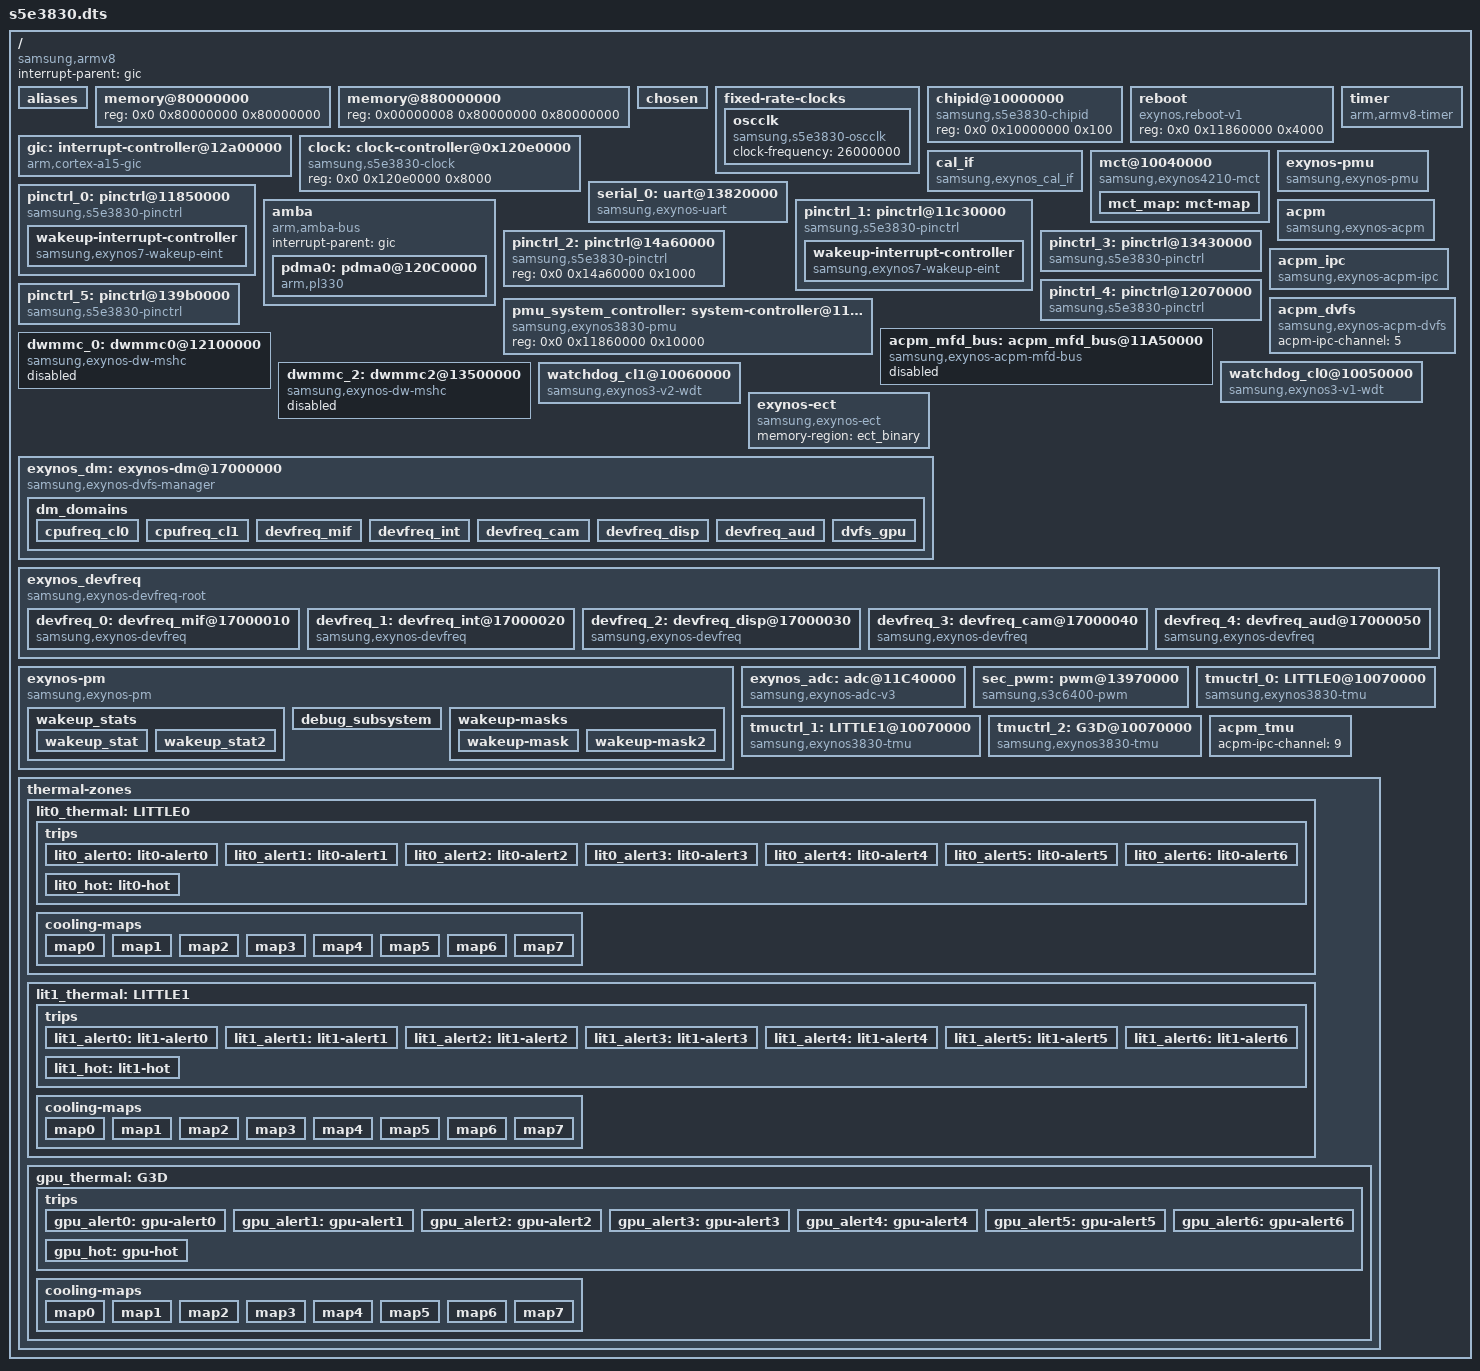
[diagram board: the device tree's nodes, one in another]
/*
 * SAMSUNG EXYNOS3830 SoC device tree source
 *
 * Copyright (c) 2018 Samsung Electronics Co., Ltd.
 *		http://www.samsung.com
 *
 * SAMSUNG EXYNOS3830 SoC device nodes are listed in this file.
 * EXYNOS based board files can include this file and provide
 * values for board specfic bindings.
 *
 * This program is free software; you can redistribute it and/or modify
 * it under the terms of the GNU General Public License version 2 as
 * published by the Free Software Foundation.
 */

/dts-v1/;
//#include <dt-bindings/clock/exynosXXXX.h>
#include <dt-bindings/interrupt-controller/arm-gic.h>
#include <dt-bindings/interrupt-controller/s5e3830.h>
#include <dt-bindings/clock/s5e3830.h>
#include <dt-bindings/soc/samsung/s5e3830-dm.h>
#include <dt-bindings/soc/samsung/s5e3830-devfreq.h>
#include <dt-bindings/soc/samsung/exynos_pm_qos.h>
#include "s5e3830-pinctrl.dtsi"
#include "s5e3830-usi.dtsi"
#include "s5e3830-rmem.dtsi"
#include "s5e3830-debug.dtsi"
#include "s5e3830-dma-heap.dtsi"
#include "s5e3830-sysmmu.dtsi"
#include "s5e3830-mali.dtsi"
#include "s5e3830-cpu.dtsi"
#include "s5e3830-ems.dtsi"
#include "s5e3830-dpu.dtsi"
#include "s5e3830-usb.dtsi"
#include "s5e3830-security.dtsi"
#include "s5e3830-pm-domains.dtsi"
#include "s5e3830-bts.dtsi"
#include "s5e3830-wlbt.dtsi"
#include "s5e3830-m2m.dtsi"

/ {
	compatible = "samsung,armv8", "samsung,exynos3830";
	interrupt-parent = <&gic>;
	#address-cells = <2>;
	#size-cells = <1>;

	aliases {
		pinctrl0 = &pinctrl_0;
		pinctrl1 = &pinctrl_1;
		pinctrl2 = &pinctrl_2;
		pinctrl3 = &pinctrl_3;
		pinctrl4 = &pinctrl_4;
		pinctrl5 = &pinctrl_5;
		uart0 = &serial_0;

		mshc0 = &dwmmc_0;
		mshc2 = &dwmmc_2;
	};

                        memory@80000000 {
                                device_type = "memory";
                                reg = <0x0 0x80000000 0x80000000>;
                        };

                        memory@880000000 {
                                device_type = "memory";
                                reg = <0x00000008 0x80000000 0x80000000>;
                        };

                        chosen {
				bootargs = "earlycon=exynos4210,0x13820000 console=ttySAC0,115200n8 androidboot.console=ttySAC0 s3c2410_wdt.tmr_atboot=1  androidboot.boot_devices=12100000.dwmmc0 clocksource=arch_sys_counter clk_ignore_unused androidboot.hardware=s5e3830 printk.devkmsg=on firmware_class.path=/vendor/firmware";
                                linux,initrd-start = <0x84000000>;
                                linux,initrd-end = <0x847FFFFF>;
                        };

                        fixed-rate-clocks {
                                oscclk {
                                        compatible = "samsung,s5e3830-oscclk";
                                        clock-frequency = <26000000>;
                                };
                        };



	chipid@10000000 {
		compatible = "samsung,s5e3830-chipid";
		reg = <0x0 0x10000000 0x100>;
	};

	reboot {
		compatible = "exynos,reboot-v1";
		reg = <0x0 0x11860000 0x4000>;
	};

	gic:interrupt-controller@12a00000 {
		compatible = "arm,cortex-a15-gic", "arm,cortex-a9-gic";
		#interrupt-cells = <3>;
		#address-cells = <0>;
		interrupt-controller;
		reg =	<0x0 0x12a01000 0x1000>,
			<0x0 0x12a02000 0x1000>,
			<0x0 0x12a04000 0x2000>,
			<0x0 0x12a06000 0x2000>;
		interrupts = <1 9 0xf04>;
	};

	timer {
	        compatible = "arm,armv8-timer";
		interrupts = <GIC_PPI 13
				(GIC_CPU_MASK_SIMPLE(8) | IRQ_TYPE_LEVEL_LOW)>,
			     <GIC_PPI 14
				(GIC_CPU_MASK_SIMPLE(8) | IRQ_TYPE_LEVEL_LOW)>,
			     <GIC_PPI 11
				(GIC_CPU_MASK_SIMPLE(8) | IRQ_TYPE_LEVEL_LOW)>,
			     <GIC_PPI 10
				(GIC_CPU_MASK_SIMPLE(8) | IRQ_TYPE_LEVEL_LOW)>;
	        clock-frequency = <26000000>;
		use-clocksource-only;
		use-physical-timer;
	};

	clock: clock-controller@0x120e0000 {
		compatible = "samsung,s5e3830-clock";
		reg = <0x0 0x120e0000 0x8000>;
		#clock-cells = <1>;
	};

	 cal_if {
                compatible = "samsung,exynos_cal_if";
                reg = <0x0 0x120e0000 0x8000>;
                acpm-ipc-channel = <0>;
        };

	mct@10040000 {
		compatible = "samsung,exynos4210-mct";
		reg = <0x0 0x10040000 0x800>;
		interrupt-controller;
		#interrupt-cells = <1>;
		interrupt-parent = <&mct_map>;
		interrupts =	<0>, <1>, <2>, <3>,
				<4>, <5>, <6>, <7>,
				<8>, <9>, <10>, <11>;
		clocks = <&clock 1>, <&clock 21>;
		clock-names = "fin_pll", "mct";
		use-clockevent-only;

		mct_map: mct-map {
			#interrupt-cells = <1>;
			#address-cells = <0>;
			#size-cells = <0>;
			interrupt-map = <0 &gic 0 INTREQ__MCT_G0 IRQ_TYPE_LEVEL_HIGH>,
					<1 &gic 0 INTREQ__MCT_G1 IRQ_TYPE_LEVEL_HIGH>,
					<2 &gic 0 INTREQ__MCT_G2 IRQ_TYPE_LEVEL_HIGH>,
					<3 &gic 0 INTREQ__MCT_G3 IRQ_TYPE_LEVEL_HIGH>,
					<4 &gic 0 INTREQ__MCT_L0 IRQ_TYPE_LEVEL_HIGH>,
					<5 &gic 0 INTREQ__MCT_L1 IRQ_TYPE_LEVEL_HIGH>,
					<6 &gic 0 INTREQ__MCT_L2 IRQ_TYPE_LEVEL_HIGH>,
					<7 &gic 0 INTREQ__MCT_L3 IRQ_TYPE_LEVEL_HIGH>,
					<8 &gic 0 INTREQ__MCT_L4 IRQ_TYPE_LEVEL_HIGH>,
					<9 &gic 0 INTREQ__MCT_L5 IRQ_TYPE_LEVEL_HIGH>,
					<10 &gic 0 INTREQ__MCT_L6 IRQ_TYPE_LEVEL_HIGH>,
					<11 &gic 0 INTREQ__MCT_L7 IRQ_TYPE_LEVEL_HIGH>;
		};
	};

	serial_0: uart@13820000 {
		compatible = "samsung,exynos-uart";
		samsung,separate-uart-clk;
		reg = <0x0 0x13820000 0x100>;
		samsung,fifo-size = <64>;
		interrupts = <0 INTREQ__UART 0>;
		pinctrl-names = "default";
		pinctrl-0 = <&uart0_bus>;
		samsung,console-dbg;
		samsung,usi-serial-v2;
		samsung,dbg-uart-ch;
		samsung,dbg-uart-baud = <115200>;
		samsung,dbg-word-len = <8>;
		clocks = <&clock GATE_UART_QCH>, <&clock DOUT_UART>;
		clock-names = "gate_uart_clk0", "ipclk_uart0";
		status = "okay";
	};
	/* TBD */
/*
	dwmmc_2: dwmmc2@13D00000 {
		compatible = "samsung,exynos-dw-mshc";
		reg = <0x0 0x13D00000 0x2000>;
		reg-names = "dw_mmc";
		interrupts = <0 250 0>;
		#address-cells = <1>;
		#size-cells = <0>;

		clocks = <&clock MMC_CARD>, <&clock GATE_MMC_CARD>;
		clock-names = "ciu", "ciu_gate";
		status = "disabled";
	 };
*/
	/* ALIVE */
	pinctrl_0: pinctrl@11850000 {
		compatible = "samsung,s5e3830-pinctrl";
		reg = <0x0 0x11850000 0x1000>;
		interrupts = <GIC_SPI INTREQ__ALIVE_EINT0 IRQ_TYPE_LEVEL_HIGH>,
			     <GIC_SPI INTREQ__ALIVE_EINT1 IRQ_TYPE_LEVEL_HIGH>,
			     <GIC_SPI INTREQ__ALIVE_EINT2 IRQ_TYPE_LEVEL_HIGH>,
			     <GIC_SPI INTREQ__ALIVE_EINT3 IRQ_TYPE_LEVEL_HIGH>,
			     <GIC_SPI INTREQ__ALIVE_EINT4 IRQ_TYPE_LEVEL_HIGH>,
			     <GIC_SPI INTREQ__ALIVE_EINT5 IRQ_TYPE_LEVEL_HIGH>,
			     <GIC_SPI INTREQ__ALIVE_EINT6 IRQ_TYPE_LEVEL_HIGH>,
			     <GIC_SPI INTREQ__ALIVE_EINT7 IRQ_TYPE_LEVEL_HIGH>,
			     <GIC_SPI INTREQ__ALIVE_EINT8 IRQ_TYPE_LEVEL_HIGH>,
			     <GIC_SPI INTREQ__ALIVE_EINT9 IRQ_TYPE_LEVEL_HIGH>,
			     <GIC_SPI INTREQ__ALIVE_EINT10 IRQ_TYPE_LEVEL_HIGH>,
			     <GIC_SPI INTREQ__ALIVE_EINT11 IRQ_TYPE_LEVEL_HIGH>,
			     <GIC_SPI INTREQ__ALIVE_EINT12 IRQ_TYPE_LEVEL_HIGH>,
			     <GIC_SPI INTREQ__ALIVE_EINT13 IRQ_TYPE_LEVEL_HIGH>,
			     <GIC_SPI INTREQ__ALIVE_EINT14 IRQ_TYPE_LEVEL_HIGH>,
			     <GIC_SPI INTREQ__ALIVE_EINT15 IRQ_TYPE_LEVEL_HIGH>,
			     <GIC_SPI INTREQ__ALIVE_EINT16 IRQ_TYPE_LEVEL_HIGH>,
			     <GIC_SPI INTREQ__ALIVE_EINT17 IRQ_TYPE_LEVEL_HIGH>,
			     <GIC_SPI INTREQ__ALIVE_EINT18 IRQ_TYPE_LEVEL_HIGH>,
			     <GIC_SPI INTREQ__ALIVE_EINT19 IRQ_TYPE_LEVEL_HIGH>,
			     <GIC_SPI INTREQ__ALIVE_EINT20 IRQ_TYPE_LEVEL_HIGH>,
			     <GIC_SPI INTREQ__ALIVE_EINT21 IRQ_TYPE_LEVEL_HIGH>,
			     <GIC_SPI INTREQ__ALIVE_EINT22 IRQ_TYPE_LEVEL_HIGH>,
			     <GIC_SPI INTREQ__ALIVE_EINT23 IRQ_TYPE_LEVEL_HIGH>,
			     <GIC_SPI INTREQ__ALIVE_EINT24 IRQ_TYPE_LEVEL_HIGH>,
			     <GIC_SPI INTREQ__ALIVE_EINT25 IRQ_TYPE_LEVEL_HIGH>,
			     <GIC_SPI INTREQ__ALIVE_EINT26 IRQ_TYPE_LEVEL_HIGH>,
			     <GIC_SPI INTREQ__ALIVE_EINT27 IRQ_TYPE_LEVEL_HIGH>,
			     <GIC_SPI INTREQ__ALIVE_EINT28 IRQ_TYPE_LEVEL_HIGH>,
			     <GIC_SPI INTREQ__ALIVE_EINT29 IRQ_TYPE_LEVEL_HIGH>,
			     <GIC_SPI INTREQ__ALIVE_EINT30 IRQ_TYPE_LEVEL_HIGH>,
			     <GIC_SPI INTREQ__ALIVE_EINT31 IRQ_TYPE_LEVEL_HIGH>;

		wakeup-interrupt-controller {
			compatible = "samsung,exynos7-wakeup-eint";
		};
	};

	/* DMA */
	amba {
		#address-cells = <2>;
		#size-cells = <1>;
		compatible = "arm,amba-bus";
		interrupt-parent = <&gic>;
		ranges;
		pdma0: pdma0@120C0000 {
			compatible = "arm,pl330", "arm,primecell";
			reg = <0x0 0x120C0000 0x1000>;
			interrupts = <GIC_SPI INTREQ__PDMA0 IRQ_TYPE_LEVEL_HIGH>;
			clocks = <&clock GATE_PDMA_CORE_QCH>;
			clock-names = "apb_pclk";
			#dma-cells = <1>;
			#dma-channels = <8>;
			#dma-requests = <32>;
			#dma-multi-irq = <1>;
			dma-arwrapper = <0x120C4400>,
					<0x120C4420>,
					<0x120C4440>,
					<0x120C4460>,
					<0x120C4480>,
					<0x120C44A0>,
					<0x120C44C0>,
					<0x120C44E0>;
			dma-awwrapper = <0x120C4404>,
					<0x120C4424>,
					<0x120C4444>,
					<0x120C4464>,
					<0x120C4484>,
					<0x120C44A4>,
					<0x120C44C4>,
					<0x120C44E4>;
			dma-instwrapper = <0x120C4500>;
			dma-mask-bit = <36>;
			coherent-mask-bit = <36>;
		};
	};


	/* CMGP */
	pinctrl_1: pinctrl@11c30000 {
		compatible = "samsung,s5e3830-pinctrl";
		reg = <0x0 0x11c30000 0x1000>;
		interrupts = <GIC_SPI INTREQ__CMGP_EXT_INTM00 IRQ_TYPE_LEVEL_HIGH>,
			     <GIC_SPI INTREQ__CMGP_EXT_INTM01 IRQ_TYPE_LEVEL_HIGH>,
			     <GIC_SPI INTREQ__CMGP_EXT_INTM02 IRQ_TYPE_LEVEL_HIGH>,
			     <GIC_SPI INTREQ__CMGP_EXT_INTM03 IRQ_TYPE_LEVEL_HIGH>,
			     <GIC_SPI INTREQ__CMGP_EXT_INTM04 IRQ_TYPE_LEVEL_HIGH>,
			     <GIC_SPI INTREQ__CMGP_EXT_INTM05 IRQ_TYPE_LEVEL_HIGH>,
			     <GIC_SPI INTREQ__CMGP_EXT_INTM06 IRQ_TYPE_LEVEL_HIGH>,
			     <GIC_SPI INTREQ__CMGP_EXT_INTM07 IRQ_TYPE_LEVEL_HIGH>;

		wakeup-interrupt-controller {
			compatible = "samsung,exynos7-wakeup-eint";
		};
	};

	/* AUD */
	pinctrl_2: pinctrl@14a60000 {
		compatible = "samsung,s5e3830-pinctrl";
		reg = <0x0 0x14a60000 0x1000>;
	};

	/* HSI */
	pinctrl_3: pinctrl@13430000 {
		compatible = "samsung,s5e3830-pinctrl";
		reg = <0x0 0x13430000 0x1000>;
		interrupts = <GIC_SPI INTREQ__GPIO_HSI IRQ_TYPE_LEVEL_HIGH>;
	};

	/* CORE */
	pinctrl_4: pinctrl@12070000 {
		compatible = "samsung,s5e3830-pinctrl";
		reg = <0x0 0x12070000 0x1000>;
		interrupts = <GIC_SPI INTREQ__GPIO_CORE IRQ_TYPE_LEVEL_HIGH>;
	};

	/* PERI */
	pinctrl_5: pinctrl@139b0000 {
		compatible = "samsung,s5e3830-pinctrl";
		reg = <0x0 0x139b0000 0x1000>;
		interrupts = <GIC_SPI INTREQ__GPIO_PERI IRQ_TYPE_LEVEL_HIGH>;
	};

	exynos-pmu {
                compatible = "samsung,exynos-pmu";
                samsung,syscon-phandle = <&pmu_system_controller>;
                reg = <0x0 0x11860000 0x10000>;
                reg-names = "pmu_alive";
        };

        pmu_system_controller: system-controller@11860000 {
                compatible = "samsung,exynos3830-pmu", "syscon";
                reg = <0x0 0x11860000 0x10000>;
        };

	acpm {
		compatible = "samsung,exynos-acpm";
		#address-cells = <2>;
		#size-cells = <1>;
		acpm-ipc-channel = <4>;
		fvmap_offset = <0xA000>;
		reg = <0x0 0x11830000 0x1000>;		/* TIMER_APM */
		reg-names = "timer_apm";
		peritimer-cnt = <0xFFFF>;
	};

	acpm_ipc {
		compatible = "samsung,exynos-acpm-ipc";
		#address-cells = <2>;
		#size-cells = <1>;
		interrupts = <0 INTREQ__MAILBOX_APM2AP IRQ_TYPE_LEVEL_HIGH>;	/* AP2APM MAILBOX SPI NUM*/
		reg = <0x0 0x11900000 0x1000>,		/* AP2APM MAILBOX */
			<0x0 0x2039000 0x30000>;	/* APM SRAM */
		initdata-base = <0x7000>;
		num-timestamps = <32>;
		debug-log-level = <0>;
		logging-period = <500>;
		dump-base = <0x203C000>;
		dump-size = <0x2D000>;			/* 180KB */
	};

	acpm_dvfs {
		compatible = "samsung,exynos-acpm-dvfs";
		acpm-ipc-channel = <5>;
	};

	acpm_mfd_bus: acpm_mfd_bus@11A50000 {
		compatible = "samsung,exynos-acpm-mfd-bus";
		status = "disabled";
	};

	 dwmmc_0: dwmmc0@12100000 {
		 compatible = "samsung,exynos-dw-mshc";
		 reg = <0x0 0x12100000 0x2000>,
			 <0x0 0x12108000 0x200>;
		 reg-names = "dw_mmc",
			 "cmdq_mem";
		 interrupts = <0 INTREQ__MMC_EMBD_CORE 0>;
		 #address-cells = <1>;
		 #size-cells = <0>;
		 clocks = <&clock DOUT_CORE_MMC_EMBD>, <&clock GATE_MMC_EMBD_QCH>;
		 clock-names = "ciu", "ciu_gate";
		 status = "disabled";
		 fmp-id = <0>;
		 smu-id = <0>;
	 };

       dwmmc_2: dwmmc2@13500000 {
                compatible = "samsung,exynos-dw-mshc";
                reg = <0x0 0x13500000 0x2000>;
                reg-names = "dw_mmc";
                interrupts = <0 INTREQ__MMC_CARD 0>;
                #address-cells = <1>;
                #size-cells = <0>;
                clocks = <&clock HSI_MMC_CARD>, <&clock GATE_MMC_CARD_QCH>;
                clock-names = "ciu", "ciu_gate";
                samsung,power-domain = <&pd_hsi>;
                status = "disabled";
        };


	/* TODO */
	pmu_system_controller: system-controller@11860000 {
	       compatible = "samsung,exynos3830-pmu", "syscon";
	       reg = <0x0 0x11860000 0x10000>;
	};

        watchdog_cl0@10050000 {
                compatible = "samsung,exynos3-v1-wdt";
                reg = <0x0 0x10050000 0x100>;
                interrupts = <GIC_SPI INTREQ__WDT_0 IRQ_TYPE_LEVEL_HIGH>;
                clocks = <&clock OSCCLK>, <&clock GATE_WDT_0_QCH>;
                clock-names = "rate_watchdog", "gate_watchdog";
                timeout-sec = <30>;
                samsung,syscon-phandle = <&pmu_system_controller>;
                index = <0>; /* if little cluster then index is 0*/
       };

       watchdog_cl1@10060000 {
                compatible = "samsung,exynos3-v2-wdt";
                reg = <0x0 0x10060000 0x100>;
                interrupts = <GIC_SPI INTREQ__WDT_1 IRQ_TYPE_LEVEL_HIGH>;
                clocks = <&clock OSCCLK>, <&clock GATE_WDT_1_QCH>;
                clock-names = "rate_watchdog", "gate_watchdog";
                timeout-sec = <30>;
                samsung,syscon-phandle = <&pmu_system_controller>;
                index = <1>; /* if little cluster then index is 0*/
		use_multistage_wdt; /* Use FIQ debug watchdog */
       };
	
	exynos-ect {
		compatible = "samsung,exynos-ect";
		memory-region = <&ect_binary>;
	};

	exynos_dm: exynos-dm@17000000 {
		compatible = "samsung,exynos-dvfs-manager";
		reg = <0x0 0x17000000 0x0>;
		acpm-ipc-channel = <1>;
		dm_domains {
			cpufreq_cl0 {
				dm-index = <DM_CPU_CL0>;
				available = "true";
				cal_id = <ACPM_DVFS_CPUCL0>;
				dm_type_name = "dm_cpu_cl0";
			};
			cpufreq_cl1 {
				dm-index = <DM_CPU_CL1>;
				available = "true";
				cal_id = <ACPM_DVFS_CPUCL1>;
				dm_type_name = "dm_cpu_cl1";
			};
			devfreq_mif {
				dm-index = <DM_MIF>;
				available = "true";
				policy_use = "true";
				cal_id = <ACPM_DVFS_MIF>;
				dm_type_name = "dm_mif";
			};
			devfreq_int {
				dm-index = <DM_INT>;
				available = "true";
				policy_use = "true";
				cal_id = <ACPM_DVFS_INT>;
				dm_type_name = "dm_int";
			};
			devfreq_cam {
				dm-index = <DM_CAM>;
				available = "true";
				cal_id = <ACPM_DVFS_CAM>;
				dm_type_name = "dm_cam";
			};
			devfreq_disp {
				dm-index = <DM_DISP>;
				available = "true";
				cal_id = <ACPM_DVFS_DISP>;
				dm_type_name = "dm_disp";
			};
			devfreq_aud {
				dm-index = <DM_AUD>;
				available = "true";
				cal_id = <ACPM_DVFS_AUD>;
				dm_type_name = "dm_aud";
			};
			dvfs_gpu {
				dm-index = <DM_GPU>;
				available = "false";
				cal_id = <ACPM_DVFS_G3D>;
				dm_type_name = "dm_gpu";
			};
		};
	};

	exynos_devfreq {
		compatible = "samsung,exynos-devfreq-root";
		#address-cells = <2>;
		#size-cells = <1>;
		ranges;
		devfreq_0: devfreq_mif@17000010 {
			compatible = "samsung,exynos-devfreq";
			reg = <0x0 0x17000010 0x0>;
			devfreq_type = <DEVFREQ_MIF>;
			devfreq_domain_name = "MIF";
			pm_qos_class = <PM_QOS_BUS_THROUGHPUT>; /* PM_QOS_BUS_THROUGHPUT */
			pm_qos_class_max = <PM_QOS_BUS_THROUGHPUT_MAX>; /* PM_QOS_BUS_THROUGHPUT_MAX */
			ess_flag = <ESS_FLAG_MIF>;
			dm-index = <DM_MIF>;

			/* Delay time */
			use_delay_time = "false";

			freq_info = <1539000 421000 421000 421000 1539000 421000>;
			/* initial_freq, default_qos, suspend_freq, min_freq, max_freq reboot_freq */

			/* Booting value */
			boot_info = <40 1539000>;
			/* boot_qos_timeout, boot_freq */

			/* governor data */
			governor = <SIMPLE_INTERACTIVE>;

			bts_update = "false";
			dfs_id = <ACPM_DVFS_MIF>;
			acpm-ipc-channel = <1>;
			use_acpm = "true";
			update_fvp = "true";
		};

		devfreq_1: devfreq_int@17000020 {
			compatible = "samsung,exynos-devfreq";
			reg = <0x0 0x17000020 0x0>;
			devfreq_type = <DEVFREQ_INT>;
			devfreq_domain_name = "INT";
			pm_qos_class = <PM_QOS_DEVICE_THROUGHPUT>; /* PM_QOS_DEVICE_THROUGHPUT */
			pm_qos_class_max = <PM_QOS_DEVICE_THROUGHPUT_MAX>; /* PM_QOS_DEVICE_THROUGHPUT_MAX */
			ess_flag = <ESS_FLAG_INT>;
			dm-index = <DM_INT>;

			/* Delay time */
			use_delay_time = "false";

			freq_info = <667000 50000 50000 50000 667000 667000>;
			/* <initial_freq, default_qos, suspend_freq, min, max, reboot_freq> */

			/* Booting value */
			boot_info = <40 667000>;
			/* boot_qos_timeout, boot_freq */

			/* governor data */
			governor = <SIMPLE_INTERACTIVE>;

			bts_update = "false";
			dfs_id = <ACPM_DVFS_INT>;
			acpm-ipc-channel = <1>;
			use_acpm = "true";
		};

		devfreq_2: devfreq_disp@17000030 {
			compatible = "samsung,exynos-devfreq";
			reg = <0x0 0x17000030 0x0>;
			devfreq_type = <DEVFREQ_DISP>;
			devfreq_domain_name = "DISP";
			pm_qos_class = <PM_QOS_DISPLAY_THROUGHPUT>; /* PM_QOS_DISPLAY_THROUGHPUT */
			pm_qos_class_max = <PM_QOS_DISPLAY_THROUGHPUT_MAX>; /* PM_QOS_DISPLAY_THROUGHPUT_MAX */
			ess_flag = <ESS_FLAG_DISP>;
			dm-index = <DM_DISP>;

			/* Delay time */
			use_delay_time = "false";

			freq_info = <400000 50000 50000 50000 400000 400000>;
			/* <initial_freq, default_qos, suspend_freq, min, max, reboot_freq> */

			/* Booting value */
			boot_info = <40 400000>;
			/* boot_qos_timeout, boot_freq */

			/* governor data */
			governor = <SIMPLE_INTERACTIVE>;

			bts_update = "false";
			dfs_id = <ACPM_DVFS_DISP>;
		};

		devfreq_3: devfreq_cam@17000040 {
			compatible = "samsung,exynos-devfreq";
			reg = <0x0 0x17000040 0x0>;
			devfreq_type = <DEVFREQ_CAM>;
			devfreq_domain_name = "CAM";
			pm_qos_class = <PM_QOS_CAM_THROUGHPUT>; /* PM_QOS_CAM_THROUGHPUT */
			pm_qos_class_max = <PM_QOS_CAM_THROUGHPUT_MAX>; /* PM_QOS_CAM_THROUGHPUT_MAX */
			ess_flag = <ESS_FLAG_CAM>;
			dm-index = <DM_CAM>;

			/* Delay time */
			use_delay_time = "false";

			freq_info = <690000 650000 65000 650000 690000 650000>;
			/* <initial, default_qos, suspend_freq, min, max, reboot_freq> */

			/* Booting value */
			boot_info = <40 650000>;
			/* boot_qos_timeout, boot_freq */

			/* governor data */
			governor = <SIMPLE_INTERACTIVE>;

			bts_update = "false";

			dfs_id = <ACPM_DVFS_CAM>;
		};

		devfreq_4: devfreq_aud@17000050 {
			compatible = "samsung,exynos-devfreq";
			reg = <0x0 0x17000050 0x0>;
			devfreq_type = <DEVFREQ_AUD>;
			devfreq_domain_name = "AUD";
			pm_qos_class = <PM_QOS_AUD_THROUGHPUT>; /* PM_QOS_AUD_THROUGHPUT */
			pm_qos_class_max = <PM_QOS_AUD_THROUGHPUT_MAX>; /* PM_QOS_AUD_THROUGHPUT_MAX */
			ess_flag = <ESS_FLAG_AUD>;
			dm-index = <DM_AUD>;

			/* Delay time */
			use_delay_time = "false";

			freq_info = <1033000 259000 259000 259000 1033000 259000>;
			/* <initial, default_qos, suspend_freq, min, max, reboot_freq> */

			/* Booting value */
			boot_info = <40 259000>;
			/* boot_qos_timeout, boot_freq */

			/* governor data */
			governor = <SIMPLE_INTERACTIVE>;

			bts_update = "false";
			dfs_id = <ACPM_DVFS_AUD>;

			power-domains = <&pd_aud>;
			pd_name = "pd-aud";
		};
	};

	exynos-pm {
		compatible = "samsung,exynos-pm";
		reg = <0x0 0x11850000 0x1000>,
		    <0x0 0x12a01200 0x100>,
		    <0x0 0x11a50000 0x2000>;
		reg-names = "gpio_alive_base",
			"gicd_ispendrn_base",
			"i3c_base";
		num-eint = <16>;
		num-gic = <16>;
		suspend_mode_idx = <8>;         /* SYS_SLEEP */
		suspend_psci_idx = <1024>;      /* PSCI_SYSTEM_SLEEP */

		usbl2_suspend_available = <0>;  /* SYS_SLEEP_USBL2 */
		usbl2_suspend_mode_idx = <12>;  /* PSCI_SYSTEM_SLEEP */

		/* WAKEUP_STAT,      WAKEUP2_STAT*/
		wakeup_stat = <0x3950>,         <0x3954>;

		wake_lock = <0>;		/* 1: held wake_lock */

		vgpio_tx_monitor = <0x1700>;
		wakeup_stats {
			wakeup_stat {
				ws-name =
					"RTC_ALARM",		/* [ 0] */
					"RTC_TICK",		/* [ 1] */
					"TRTC_ALARM",		/* [ 2] */
					"TRTC_TICK",		/* [ 3] */
					"RESERVED",		/* [ 4] */
					"CMGP2PMU_AP_EINT0",	/* [ 5] */
					"CMGP2PMU_AP_EINT1",	/* [ 6] */
					"AUD_ABOX_GIC400",	/* [ 7] */
					"MAILBOX_CHUB2AP",	/* [ 8] */
					"MAILBOX_GNSS2AP",	/* [ 9] */
					"MAILBOX_WLBT2AP",	/* [10] */
					"MAILBOX_APM2AP",	/* [11] */
					"MAILBOX_CP2AP",	/* [12] */
					"S_MAILBOX_CP2AP",	/* [13] */
					"CHUB_WDT",		/* [14] */
					"EINT",			/* [15] */
					"USB_REWA",		/* [16] */
					"USB20",		/* [17] */
					"MMC_EMBD",		/* [18] */
					"MMC_CARD",		/* [19] */
					"TIMER",		/* [20] */
					"CP_RESET_REQ",		/* [21] */
					"GNSS_RESET_REQ",	/* [22] */
					"GNSS_ACTIVE",		/* [23] */
					"GNSS_WAKEUP_REQ",	/* [24] */
					"WLBT_RESET_REQ",	/* [25] */
					"WLBT_ACTIVE",		/* [26] */
					"CLUSTER0_CPU0_nIRQ",	/* [27] */
					"CLUSTER0_CPU1_nIRQ",	/* [28] */
					"CLUSTER0_CPU2_nIRQ",	/* [29] */
					"CLUSTER0_CPU3_nIRQ",	/* [30] */
					"RESERVED";		/* [31] */
			};
			wakeup_stat2 {
				ws-name =
					"PMIC_CODEC_IRQ",	/* [ 0] */
					"PMIC_IRQ",		/* [ 1] */
					"CLUSTER1_CPU0_nIRQ",	/* [ 2] */
					"CLUSTER1_CPU1_nIRQ",	/* [ 3] */
					"CLUSTER1_CPU2_nIRQ",	/* [ 4] */
					"CLUSTER1_CPU3_nIRQ";	/* [ 5] */
			};
		};
		debug_subsystem {
			sfr-name =
				"CP_OUT",
				"GNSS_OUT",
				"WLBT_OUT",
				"MIF_OUT",
				"CHUB_STATES";
			sfr-offset =
				<0x3020>,
				<0x30a0>,
				<0x3120>,
				<0x3820>,
				<0x1f88>;
		};
		wakeup-masks {
			/*
			 * wakeup_mask configuration
			 *	        SICD		SICD_CPD	AFTR		STOP
			 *              LPD		LPA		ALPA		DSTOP
			 *              SLEEP		SLEEP_VTS_ON	SLEEP_AUD_ON	FAPO
			 *		USB_L2		HSI2ON
			 */
			wakeup-mask {
				mask = <0xffffffff>,	<0x0>,		<0x0>,		<0x0>,
				       <0x0>,		<0x0>,		<0x0>,		<0x0>,
				       <0x0360ffef>,	<0x8007ff6f>,	<0x8007ff6f>,	<0x0>,
				       <0x8007ff6f>,	<0x8007ff6f>;
				mask-offset = <0x3944>;
				stat-offset = <0x3950>;
			};
			wakeup-mask2 {
				mask = <0x3e1e>,	<0x0>,		<0x0>,		<0x0>,
				       <0x0>,		<0x0>,		<0x0>,		<0x0>,
				       <0x0>,	<0x3e1e>,	<0x3e1e>,	<0x0>,
				       <0x3e1e>,	<0x3e1e>;
				mask-offset = <0x3964>;
				stat-offset = <0x3954>;
			};
		};
	};
	exynos_adc: adc@11C40000 {
		    compatible = "samsung,exynos-adc-v3";
		    reg = <0x0 0x11C40000 0x100>;
		    interrupts = <GIC_SPI INTREQ__ADC_CMGP2AP IRQ_TYPE_LEVEL_HIGH>;
		    #io-channel-cells = <1>;
		    io-channel-ranges;
		    clocks = <&clock GATE_ADC_CMGP_QCH_S0>;
		    clock-names = "gate_adcif";
	};

	sec_pwm: pwm@13970000 {
                compatible = "samsung,s3c6400-pwm";
                reg = <0x0 0x13970000 0x1000>;
                samsung,pwm-outputs = <0>, <1>, <2>, <3>, <4>;
                #pwm-cells = <3>;
                clocks = <&clock GATE_PWM_MOTOR_QCH>, <&clock OSCCLK>;
                clock-names = "pwm_pclk", "pwm_sclk";
                status = "ok";
	};

	tmuctrl_0: LITTLE0@10070000 {
		compatible = "samsung,exynos3830-tmu";
		reg = <0x0 0x10070000 0x800>;
		interrupts = <GIC_SPI INTREQ__TMU IRQ_TYPE_LEVEL_HIGH>;
		tmu_name = "LITTLE0";
		id = <0>;
		sensors = <2>;
		cal_id = <ACPM_DVFS_CPUCL0>;
		#include "s5e3830-tmu-sensor-conf.dtsi"
	};

	tmuctrl_1: LITTLE1@10070000 {
		compatible = "samsung,exynos3830-tmu";
		reg = <0x0 0x10070000 0x800>;
		interrupts = <GIC_SPI INTREQ__TMU IRQ_TYPE_LEVEL_HIGH>;
		tmu_name = "LITTLE1";
		id = <1>;
		sensors = <4>;
		cal_id = <ACPM_DVFS_CPUCL1>;
		hotplug_enable = <1>;
		hotplug_in_threshold = <91>;
		hotplug_out_threshold = <96>;
		cpu_domain = "4-7";

		thermal_status_level = <80000 85000 90000>;
		#include "s5e3830-tmu-sensor-conf.dtsi"
	};

	tmuctrl_2: G3D@10070000 {
		compatible = "samsung,exynos3830-tmu";
		reg = <0x0 0x10070000 0x800>;
		interrupts = <GIC_SPI INTREQ__TMU IRQ_TYPE_LEVEL_HIGH>;
		tmu_name = "G3D";
		id = <2>;
		sensors = <8>;
		#include "s5e3830-tmu-sensor-conf.dtsi"
	};

	acpm_tmu {
		acpm-ipc-channel = <9>;
	};

	thermal-zones {
		lit0_thermal: LITTLE0 {
			zone_name = "LITTLE0_THERMAL";
			polling-delay-passive = <0>;
			polling-delay = <1000>;
			thermal-sensors = <&tmuctrl_0>;

			trips {
				lit0_alert0: lit0-alert0 {
					temperature = <20000>;
					hysteresis = <5000>; /* millicelsius */
					type = "active";
				};
				lit0_alert1: lit0-alert1 {
					temperature = <76000>; /* millicelsius */
					hysteresis = <2000>; /* millicelsius */
					type = "active";
				};
				lit0_alert2: lit0-alert2 {
					temperature = <81000>; /* millicelsius */
					hysteresis = <5000>; /* millicelsius */
					type = "active";
				};
				lit0_alert3: lit0-alert3 {
					temperature = <86000>; /* millicelsius */
					hysteresis = <5000>; /* millicelsius */
					type = "active";
				};
				lit0_alert4: lit0-alert4 {
					temperature = <91000>; /* millicelsius */
					hysteresis = <5000>; /* millicelsius */
					type = "active";
				};
				lit0_alert5: lit0-alert5 {
					temperature = <96000>; /* millicelsius */
					hysteresis = <5000>; /* millicelsius */
					type = "active";
				};
				lit0_alert6: lit0-alert6 {
					temperature = <101000>; /* millicelsius */
					hysteresis = <5000>; /* millicelsius */
					type = "active";
				};
				lit0_hot: lit0-hot {
					temperature = <115000>; /* millicelsius */
					hysteresis = <5000>; /* millicelsius */
					type = "hot";
				};
			};
			cooling-maps {
				map0 {
					trip = <&lit0_alert0>;
					cooling-device = <&cpufreq_domain0 0 0>;
				};
				map1 {
					trip = <&lit0_alert1>;
					cooling-device = <&cpufreq_domain0 0 0>;
				};
				map2 {
					trip = <&lit0_alert2>;
					cooling-device = <&cpufreq_domain0 0 0>;
				};
				map3 {
					trip = <&lit0_alert3>;
					cooling-device = <&cpufreq_domain0 0 0>;
				};
				map4 {
					trip = <&lit0_alert4>;
					cooling-device = <&cpufreq_domain0 0 0>;
				};
				map5 {
					trip = <&lit0_alert5>;
					cooling-device = <&cpufreq_domain0 0 0>;
				};
				map6 {
					trip = <&lit0_alert6>;
					cooling-device = <&cpufreq_domain0 0 0>;
				};
				map7 {
					trip = <&lit0_hot>;
					cooling-device = <&cpufreq_domain0 0 0>;
				};
			};
		};

		lit1_thermal: LITTLE1 {
			zone_name = "LITTLE1_THERMAL";
			polling-delay-passive = <0>;
			polling-delay = <0>;
			thermal-sensors = <&tmuctrl_1>;

			trips {
				lit1_alert0: lit1-alert0 {
					temperature = <20000>;
					hysteresis = <5000>; /* millicelsius */
					type = "active";
				};
				lit1_alert1: lit1-alert1 {
					temperature = <76000>; /* millicelsius */
					hysteresis = <2000>; /* millicelsius */
					type = "active";
				};
				lit1_alert2: lit1-alert2 {
					temperature = <81000>; /* millicelsius */
					hysteresis = <5000>; /* millicelsius */
					type = "active";
				};
				lit1_alert3: lit1-alert3 {
					temperature = <86000>; /* millicelsius */
					hysteresis = <5000>; /* millicelsius */
					type = "active";
				};
				lit1_alert4: lit1-alert4 {
					temperature = <91000>; /* millicelsius */
					hysteresis = <5000>; /* millicelsius */
					type = "active";
				};
				lit1_alert5: lit1-alert5 {
					temperature = <96000>; /* millicelsius */
					hysteresis = <5000>; /* millicelsius */
					type = "active";
				};
				lit1_alert6: lit1-alert6 {
					temperature = <101000>; /* millicelsius */
					hysteresis = <5000>; /* millicelsius */
					type = "active";
				};
				lit1_hot: lit1-hot {
					temperature = <115000>; /* millicelsius */
					hysteresis = <5000>; /* millicelsius */
					type = "hot";
				};
			};
			cooling-maps {
				map0 {
					trip = <&lit1_alert0>;
					cooling-device = <&cpufreq_domain1 0 0>;
				};
				map1 {
					trip = <&lit1_alert1>;
					cooling-device = <&cpufreq_domain1 0 0>;
				};
				map2 {
					trip = <&lit1_alert2>;
					cooling-device = <&cpufreq_domain1 0 0>;
				};
				map3 {
					trip = <&lit1_alert3>;
					cooling-device = <&cpufreq_domain1 0 0>;
				};
				map4 {
					trip = <&lit1_alert4>;
					cooling-device = <&cpufreq_domain1 0 0>;
				};
				map5 {
					trip = <&lit1_alert5>;
					cooling-device = <&cpufreq_domain1 0 0>;
				};
				map6 {
					trip = <&lit1_alert6>;
					cooling-device = <&cpufreq_domain1 0 0>;
				};
				map7 {
					trip = <&lit1_hot>;
					cooling-device = <&cpufreq_domain1 0 0>;
				};
			};
		};

		gpu_thermal: G3D {
			zone_name = "G3D_THERMAL";
			polling-delay-passive = <0>;
			polling-delay = <0>;
			thermal-sensors = <&tmuctrl_2>;

			trips {
				gpu_alert0: gpu-alert0 {
					temperature = <20000>;
					hysteresis = <5000>; /* millicelsius */
					type = "active";
				};
				gpu_alert1: gpu-alert1 {
					temperature = <76000>; /* millicelsius */
					hysteresis = <2000>; /* millicelsius */
					type = "active";
				};
				gpu_alert2: gpu-alert2 {
					temperature = <81000>; /* millicelsius */
					hysteresis = <5000>; /* millicelsius */
					type = "active";
				};
				gpu_alert3: gpu-alert3 {
					temperature = <86000>; /* millicelsius */
					hysteresis = <5000>; /* millicelsius */
					type = "active";
				};
				gpu_alert4: gpu-alert4 {
					temperature = <91000>; /* millicelsius */
					hysteresis = <5000>; /* millicelsius */
					type = "active";
				};
				gpu_alert5: gpu-alert5 {
					temperature = <96000>; /* millicelsius */
					hysteresis = <5000>; /* millicelsius */
					type = "active";
				};
				gpu_alert6: gpu-alert6 {
					temperature = <101000>; /* millicelsius */
					hysteresis = <5000>; /* millicelsius */
					type = "active";
				};
				gpu_hot: gpu-hot {
					temperature = <115000>; /* millicelsius */
					hysteresis = <5000>; /* millicelsius */
					type = "hot";
				};
			};
			cooling-maps {
				map0 {
					trip = <&gpu_alert0>;
					cooling-device = <&mali 0 0>;
				};
				map1 {
					trip = <&gpu_alert1>;
					cooling-device = <&mali 0 0>;
				};
				map2 {
					trip = <&gpu_alert2>;
					cooling-device = <&mali 0 0>;
				};
				map3 {
					trip = <&gpu_alert3>;
					cooling-device = <&mali 0 0>;
				};
				map4 {
					trip = <&gpu_alert4>;
					cooling-device = <&mali 0 0>;
				};
				map5 {
					trip = <&gpu_alert5>;
					cooling-device = <&mali 0 0>;
				};
				map6 {
					trip = <&gpu_alert6>;
					cooling-device = <&mali 0 0>;
				};
				map7 {
					trip = <&gpu_hot>;
					cooling-device = <&mali 0 0>;
				};
			};
		};
	};
};
